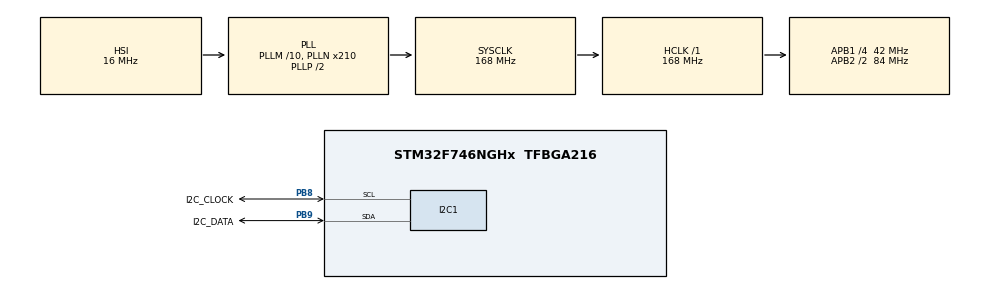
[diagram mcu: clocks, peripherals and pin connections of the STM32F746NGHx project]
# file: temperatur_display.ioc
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I2C1.Timing=0x00A0A3F7
Mcu.Family=STM32F7
Mcu.Name=STM32F746NGHx
Mcu.Package=TFBGA216
NVIC.PriorityGroup=NVIC_PRIORITYGROUP_4
NVIC.TIM8_TRG_COM_TIM14_IRQn=true\:0\:0\:false\:false\:true\:false\:true
NVIC.TimeBase=TIM8_TRG_COM_TIM14_IRQn
NVIC.TimeBaseIP=TIM14
PA13.Mode=Serial_Wire
PA13.Signal=SYS_JTMS-SWDIO
PA14.Mode=Serial_Wire
PA14.Signal=SYS_JTCK-SWCLK
PB8.GPIO_Label=I2C_CLOCK
PB8.GPIO_Speed=GPIO_SPEED_FREQ_LOW
PB8.Mode=I2C
PB8.Signal=I2C1_SCL
PB9.GPIO_Label=I2C_DATA
PB9.GPIO_Speed=GPIO_SPEED_FREQ_LOW
PB9.Mode=I2C
PB9.Signal=I2C1_SDA
PC14/OSC32_IN.Mode=LSE-External-Clock-Source
PC14/OSC32_IN.Signal=RCC_OSC32_IN
PC15/OSC32_OUT.Mode=LSE-External-Clock-Source
PC15/OSC32_OUT.Signal=RCC_OSC32_OUT
PH0/OSC_IN.Mode=HSE-External-Oscillator
PH0/OSC_IN.Signal=RCC_OSC_IN
PH1/OSC_OUT.Mode=HSE-External-Oscillator
PH1/OSC_OUT.Signal=RCC_OSC_OUT
ProjectManager.HeapSize=0x200
ProjectManager.StackSize=0x400
ProjectManager.TargetToolchain=STM32CubeIDE
RCC.AHBFreq_Value=168000000
RCC.APB1CLKDivider=RCC_HCLK_DIV4
RCC.APB1Freq_Value=42000000
RCC.APB1TimFreq_Value=84000000
RCC.APB2CLKDivider=RCC_HCLK_DIV2
RCC.APB2Freq_Value=84000000
RCC.APB2TimFreq_Value=168000000
RCC.CortexFreq_Value=168000000
RCC.HCLKFreq_Value=168000000
RCC.HSE_VALUE=25000000
RCC.HSI_VALUE=16000000
RCC.LSE_VALUE=32768
RCC.PLLM=10
RCC.PLLN=210
RCC.PLLSourceVirtual=RCC_PLLSOURCE_HSI
RCC.SYSCLKFreq_VALUE=168000000
RCC.SYSCLKSource=RCC_SYSCLKSOURCE_PLLCLK
RCC.USBFreq_Value=168000000
RCC.VCOOutputFreq_Value=336000000
VP_SYS_VS_tim14.Mode=TIM14
board=STM32F746G-DISCO

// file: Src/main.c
/* USER CODE BEGIN Header */
/**
  ******************************************************************************
  * @file           : main.c
  * @brief          : Main program body
  ******************************************************************************
  * @attention
  *
  * <h2><center>&copy; Copyright (c) 2019 STMicroelectronics.
  * All rights reserved.</center></h2>
  *
  * This software component is licensed by ST under BSD 3-Clause license,
  * the "License"; You may not use this file except in compliance with the
  * License. You may obtain a copy of the License at:
  *                        opensource.org/licenses/BSD-3-Clause
  *
  ******************************************************************************
  */
/* USER CODE END Header */

#include "main.h"

/* USER CODE BEGIN PD */
#define TEMP_SENSOR_ADDRESS (0b1001000 << 1)

#define I2C_ADDRESS_LEDMATRIX (0b11100000)
/* USER CODE END PD */

I2C_HandleTypeDef hi2c1;

/* USER CODE BEGIN PV */

uint8_t temperature = 0;
uint8_t prev_temperature = 0;

// degree celsius char
const uint8_t celsius[] =
{
0x40, 0xa0, 0x40, 0x7e, 0x81, 0x81, 0x81, 0x42
};

const uint8_t one[] =
{
0x00, 0x00, 0x21, 0x41, 0xff, 0x01, 0x01, 0x00
};

const uint8_t two[] =
{
0x00, 0x00, 0x43, 0x85, 0x89, 0x91, 0x61, 0x00
};

const uint8_t three[] =
{
0x00, 0x00, 0x42, 0x81, 0x81, 0x99, 0x66, 0x00
};

const uint8_t four[] =
{
0x00, 0x00, 0x18, 0x28, 0x48, 0xff, 0x08, 0x00
};

const uint8_t five[] =
{
0x00, 0x00, 0xf2, 0x91, 0x91, 0x91, 0x8e, 0x00
};

const uint8_t six[] =
{
0x00, 0x00, 0x7e, 0x91, 0x91, 0x91, 0x4e, 0x00
};

const uint8_t seven[] =
{
0x00, 0x00, 0x80, 0x88, 0x9f, 0xa8, 0xc0, 0x00
};

const uint8_t eight[] =
{
0x00, 0x00, 0x6e, 0x91, 0x91, 0x91, 0x6e, 0x00
};

const uint8_t nine[] =
{
0x00, 0x00, 0x72, 0x89, 0x89, 0x89, 0x7e, 0x00
};

const uint8_t zero[] =
{
0x00, 0x00, 0x7e, 0x81, 0x81, 0x81, 0x7e, 0x00
};

int first_digit;
int second_digit;

//uint8_t temp_sensor_address = 0b1001000 << 1;

/* USER CODE END PV */

void SystemClock_Config(void);
static void MX_GPIO_Init(void);
static void MX_I2C1_Init(void);
/* USER CODE BEGIN PFP */

void clear_led_matrix();
void set_led_matrix(const uint8_t* data);

/* USER CODE END PFP */

/* USER CODE BEGIN 0 */

void clear_led_matrix(){
  uint8_t buff[2];

  for(int i=0; i<16; i++)
  {
    buff[0] = i;
    buff[1] = 0x00;
    HAL_I2C_Master_Transmit(&hi2c1, I2C_ADDRESS_LEDMATRIX, buff, 2, 100);
  }
}

void set_led_matrix(const uint8_t* data){
  clear_led_matrix();
  uint8_t buff[2];

  for(int i=0; i<8; i++)
  {
      buff[0] = i*2;
      buff[1] = (data[i] >> 1) | (data[i] << 7);
      HAL_I2C_Master_Transmit(&hi2c1, I2C_ADDRESS_LEDMATRIX, buff, 2, 100);
  }
}

/* USER CODE END 0 */

int main(void)
{

  /* MCU Configuration--------------------------------------------------------*/

  /* Reset of all peripherals, Initializes the Flash interface and the Systick. */
  HAL_Init();

  /* Configure the system clock */
  SystemClock_Config();

  /* USER CODE BEGIN SysInit */
  //HAL_I2C_Init(hi2c);
  /* USER CODE END SysInit */

  /* Initialize all configured peripherals */
  MX_GPIO_Init();
  MX_I2C1_Init();
  /* USER CODE BEGIN 2 */
  uint8_t read_temp_reg = 0;
     // uint8_t read_temp_val;

  //init LED matrix
   uint8_t init1 = 0b00100001;
   uint8_t init2 = 0b10000001;

   HAL_I2C_Master_Transmit(&hi2c1, I2C_ADDRESS_LEDMATRIX, &init1, 1, 100);
   HAL_I2C_Master_Transmit(&hi2c1, I2C_ADDRESS_LEDMATRIX, &init2, 1, 100);

  /* USER CODE END 2 */

  /* Infinite loop */
  /* USER CODE BEGIN WHILE */

  while (1)
  {
    HAL_I2C_Master_Transmit(&hi2c1, TEMP_SENSOR_ADDRESS, &read_temp_reg, sizeof(read_temp_reg), 100);
    HAL_I2C_Master_Receive(&hi2c1, TEMP_SENSOR_ADDRESS, &temperature, sizeof(temperature), 100);

 //  if (temperature == prev_temperature | temperature == prev_temperature + 1 | temperature == prev_temperature - 1) {
    first_digit = prev_temperature / 10;
    second_digit = prev_temperature % 10;
    prev_temperature = temperature;
  //  }

    clear_led_matrix();

    switch (first_digit) {
    case 1:
      set_led_matrix(one);
      break;

    case 2:
      set_led_matrix(two);
      break;

    case 3:
         set_led_matrix(three);
         break;

    case 4:
         set_led_matrix(four);
         break;

    case 5:
         set_led_matrix(five);
         break;

    case 6:
         set_led_matrix(six);
         break;

    case 7:
         set_led_matrix(seven);
         break;

    case 8:
         set_led_matrix(eight);
         break;

    case 9:
         set_led_matrix(nine);
         break;

    default:
      break;
    }

    HAL_Delay(1000);

    clear_led_matrix();

    switch (second_digit) {
        case 1:
          set_led_matrix(one);
          break;

        case 2:
          set_led_matrix(two);
          break;

        case 3:
             set_led_matrix(three);
             break;

        case 4:
             set_led_matrix(four);
             break;

        case 5:
             set_led_matrix(five);
             break;

        case 6:
             set_led_matrix(six);
             break;

        case 7:
             set_led_matrix(seven);
             break;

        case 8:
             set_led_matrix(eight);
             break;

        case 9:
             set_led_matrix(nine);
             break;

        case 0:
             set_led_matrix(zero);
             break;

        default:
          break;
        }

    HAL_Delay(1000);

    clear_led_matrix();
        set_led_matrix(celsius);
        HAL_Delay(1000);

    /* USER CODE END WHILE */

  }
}

void SystemClock_Config(void)
{
  RCC_OscInitTypeDef RCC_OscInitStruct = {0};
  RCC_ClkInitTypeDef RCC_ClkInitStruct = {0};
  RCC_PeriphCLKInitTypeDef PeriphClkInitStruct = {0};

  /** Configure the main internal regulator output voltage
  */
  __HAL_RCC_PWR_CLK_ENABLE();
  __HAL_PWR_VOLTAGESCALING_CONFIG(PWR_REGULATOR_VOLTAGE_SCALE2);
  /** Initializes the CPU, AHB and APB busses clocks
  */
  RCC_OscInitStruct.OscillatorType = RCC_OSCILLATORTYPE_HSI;
  RCC_OscInitStruct.HSIState = RCC_HSI_ON;
  RCC_OscInitStruct.HSICalibrationValue = RCC_HSICALIBRATION_DEFAULT;
  RCC_OscInitStruct.PLL.PLLState = RCC_PLL_ON;
  RCC_OscInitStruct.PLL.PLLSource = RCC_PLLSOURCE_HSI;
  RCC_OscInitStruct.PLL.PLLM = 10;
  RCC_OscInitStruct.PLL.PLLN = 210;
  RCC_OscInitStruct.PLL.PLLP = RCC_PLLP_DIV2;
  RCC_OscInitStruct.PLL.PLLQ = 2;
  if (HAL_RCC_OscConfig(&RCC_OscInitStruct) != HAL_OK)
  {
    Error_Handler();
  }
  /** Initializes the CPU, AHB and APB busses clocks
  */
  RCC_ClkInitStruct.ClockType = RCC_CLOCKTYPE_HCLK|RCC_CLOCKTYPE_SYSCLK
                              |RCC_CLOCKTYPE_PCLK1|RCC_CLOCKTYPE_PCLK2;
  RCC_ClkInitStruct.SYSCLKSource = RCC_SYSCLKSOURCE_PLLCLK;
  RCC_ClkInitStruct.AHBCLKDivider = RCC_SYSCLK_DIV1;
  RCC_ClkInitStruct.APB1CLKDivider = RCC_HCLK_DIV4;
  RCC_ClkInitStruct.APB2CLKDivider = RCC_HCLK_DIV2;

  if (HAL_RCC_ClockConfig(&RCC_ClkInitStruct, FLASH_LATENCY_5) != HAL_OK)
  {
    Error_Handler();
  }
  PeriphClkInitStruct.PeriphClockSelection = RCC_PERIPHCLK_I2C1;
  PeriphClkInitStruct.I2c1ClockSelection = RCC_I2C1CLKSOURCE_PCLK1;
  if (HAL_RCCEx_PeriphCLKConfig(&PeriphClkInitStruct) != HAL_OK)
  {
    Error_Handler();
  }
}

static void MX_I2C1_Init(void)
{

  hi2c1.Instance = I2C1;
  hi2c1.Init.Timing = 0x00A0A3F7;
  hi2c1.Init.OwnAddress1 = 0;
  hi2c1.Init.AddressingMode = I2C_ADDRESSINGMODE_7BIT;
  hi2c1.Init.DualAddressMode = I2C_DUALADDRESS_DISABLE;
  hi2c1.Init.OwnAddress2 = 0;
  hi2c1.Init.OwnAddress2Masks = I2C_OA2_NOMASK;
  hi2c1.Init.GeneralCallMode = I2C_GENERALCALL_DISABLE;
  hi2c1.Init.NoStretchMode = I2C_NOSTRETCH_DISABLE;
  if (HAL_I2C_Init(&hi2c1) != HAL_OK)
  {
    Error_Handler();
  }
  /** Configure Analogue filter
  */
  if (HAL_I2CEx_ConfigAnalogFilter(&hi2c1, I2C_ANALOGFILTER_ENABLE) != HAL_OK)
  {
    Error_Handler();
  }
  /** Configure Digital filter
  */
  if (HAL_I2CEx_ConfigDigitalFilter(&hi2c1, 0) != HAL_OK)
  {
    Error_Handler();
  }

}

static void MX_GPIO_Init(void)
{

  /* GPIO Ports Clock Enable */
  __HAL_RCC_GPIOB_CLK_ENABLE();
  __HAL_RCC_GPIOA_CLK_ENABLE();
  __HAL_RCC_GPIOC_CLK_ENABLE();
  __HAL_RCC_GPIOH_CLK_ENABLE();

}

void HAL_TIM_PeriodElapsedCallback(TIM_HandleTypeDef *htim)
{
  if (htim->Instance == TIM14) {
    HAL_IncTick();
  }
}

void Error_Handler(void)
{
}

/************************ (C) COPYRIGHT STMicroelectronics *****END OF FILE****/
